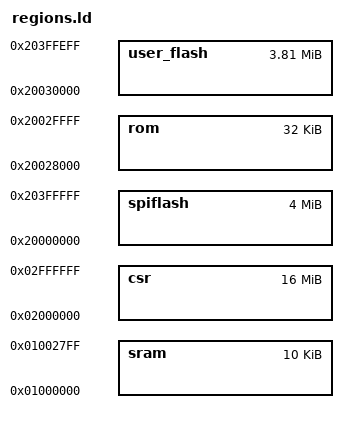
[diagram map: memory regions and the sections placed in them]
MEMORY {
	sram : ORIGIN = 0x01000000, LENGTH = 0x00002800
	csr : ORIGIN = 0x02000000, LENGTH = 0x01000000
	spiflash : ORIGIN = 0x20000000, LENGTH = 0x00400000
	rom : ORIGIN = 0x20028000, LENGTH = 0x00008000
	user_flash : ORIGIN = 0x20030000, LENGTH = 0x003cff00
}
